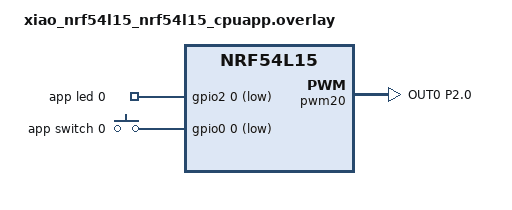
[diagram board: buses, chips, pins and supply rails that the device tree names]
/ {
    gpiocustom {
        compatible = "gpio-keys";
        appled0: appled_0 {
            gpios = <&gpio2 0 GPIO_ACTIVE_LOW>;
            label = "app led 0";
        };

        appsw0: appsw0 {
            gpios = <&gpio0 0 (GPIO_PULL_UP | GPIO_ACTIVE_LOW)>;
            label = "app switch 0";
        };
    };

    aliases {
        appled0 = &appled0;
        appsw0 = &appsw0;
        apppwm = &pwm20;
    };
};

&pinctrl {
    pwm20_default: pwm20_default {
        group1 {
            psels = <NRF_PSEL(PWM_OUT0, 2, 0)>;
        };
    };

    pwm20_sleep: pwm20_sleep {
        group1 {
            psels = <NRF_PSEL(PWM_OUT0, 2, 0)>;
        };
    };
};

&pwm20{
    status = "okay";
    pinctrl-0 = <&pwm20_default>;
    pinctrl-1 = <&pwm20_sleep>;
    pinctrl-names = "default", "sleep";
};

// // GPIO pin control
// &pinctrl {
// pwm20_default: pwm20_default {
//   group1
//   {
//     psels = <NRF_PSEL(PWM_OUT0, 2, 0)>;
//   };
// };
